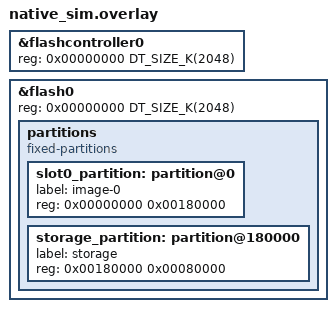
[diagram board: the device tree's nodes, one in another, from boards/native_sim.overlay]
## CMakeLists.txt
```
# SPDX-License-Identifier: GPL-3.0-or-later
#
# Method 3 (PAIRING_PASSKEY) pairing gate conformance on native_sim (T-18).
# Exercises pairing.c + client_bond.c + storage.c on a simulated LittleFS
# partition, with PAIRING_PASSKEY=y selected via prj.conf.
#
# Build:
#   ZEPHYR_TOOLCHAIN_VARIANT=host \
#     west build -p -b native_sim firmware/tests/pairing_passkey --no-sysbuild
#   west build -t run

cmake_minimum_required(VERSION 3.20.0)

find_package(Zephyr REQUIRED HINTS $ENV{ZEPHYR_BASE})
project(pairing_passkey_tests LANGUAGES C)

set(FW ${CMAKE_CURRENT_SOURCE_DIR}/../..)

target_sources(app PRIVATE
    src/main.c
    src/gesture_stub.c
    src/led_stub.c
    src/session_stub.c
    ${FW}/src/clients/pairing.c
    ${FW}/src/clients/client_bond.c
    ${FW}/src/storage/storage.c
    ${FW}/src/storage/volume_marker.c
    ${FW}/src/crypto/device_id.c
    ${FW}/src/crypto/crypto_wolfssl.c
    ${FW}/src/crypto/wc_rand.c
    ${FW}/src/crypto/zeroize.c
    ${FW}/../common/cbor/cantil_cbor.c
)

target_include_directories(app PRIVATE
    ${FW}/src
    ${FW}/include
    ${FW}/../common/cbor
)

zephyr_include_directories(${FW}/include)

# Carries WOLFSSL_USER_SETTINGS / WOLFSSL_ZEPHYR defines.
target_link_libraries(app PRIVATE wolfSSL)
```

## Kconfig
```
# SPDX-License-Identifier: GPL-3.0-or-later

mainmenu "pairing_passkey ztest"

config CANTIL_MAX_KEY_SLOTS
	int "Maximum number of key slots"
	default 8
	range 1 64

config CANTIL_MAX_CLIENT_BONDS
	int "Maximum number of host-client bonds"
	default 2
	range 1 16

config CANTIL_MAX_PEER_BONDS
	int "Maximum number of peer-device bonds"
	default 2
	range 1 8

config CANTIL_CRL_VALIDITY_SEC
	int "CRL nextUpdate window (seconds)"
	default 86400

# Pairing method symbols (flat booleans — no choice wrapper in test context).
config PAIRING_PROMISCUOUS
	bool "Method 0 — Promiscuous"
	default n

config PAIRING_TOFU
	bool "Method 1 — Silent TOFU"
	default n

config PAIRING_TAP_CONFIRM
	bool "Method 2 — Tap-confirmed bond"
	default n

config PAIRING_PASSKEY
	bool "Method 3 — Passkey + tap-confirmed bond"
	default n

config CANTIL_PAIR_TIMEOUT_SEC
	int "Pairing prompt timeout (seconds)"
	default 30

config CANTIL_PASSKEY_TIMEOUT_SEC
	int "Passkey entry timeout (seconds)"
	default 60

config CANTIL_PASSKEY_BLINK_PAUSE_MS
	int "Inter-digit pause during passkey LED blink (milliseconds)"
	default 0

source "Kconfig.zephyr"
```

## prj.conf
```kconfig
# ztest framework
CONFIG_ZTEST=y

# Pairing method under test.
CONFIG_PAIRING_PASSKEY=y
CONFIG_CANTIL_PAIR_TIMEOUT_SEC=30
CONFIG_CANTIL_PASSKEY_TIMEOUT_SEC=60
CONFIG_CANTIL_PASSKEY_BLINK_PAUSE_MS=0

CONFIG_CANTIL_MAX_CLIENT_BONDS=2
CONFIG_CANTIL_MAX_PEER_BONDS=2

# Entropy — native_sim has zephyr,native-posix-rng.
CONFIG_ENTROPY_GENERATOR=y
CONFIG_TEST_RANDOM_GENERATOR=y

# LittleFS on the sim flash partition.
CONFIG_FLASH=y
CONFIG_FLASH_MAP=y
CONFIG_FILE_SYSTEM=y
CONFIG_FILE_SYSTEM_LITTLEFS=y
CONFIG_FS_LITTLEFS_FMP_DEV=y
CONFIG_FILE_SYSTEM_MKFS=y


# Device-id source for the FICR-derived storage key.
CONFIG_HWINFO=y

CONFIG_MAIN_STACK_SIZE=8192
CONFIG_HEAP_MEM_POOL_SIZE=16384

# crc32_ieee — storage.c volume identity marker
CONFIG_CRC=y

# wolfCrypt — primitives selected by the settings header, not Kconfig.
CONFIG_WOLFSSL=y
CONFIG_WOLFSSL_BUILTIN=y
CONFIG_WOLFSSL_SETTINGS_FILE="cantil_wolfssl_user_settings.h"
```

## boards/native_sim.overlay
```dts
/* Same flash layout as session_slot tests — 512 KB storage partition. */

&flashcontroller0 {
	reg = <0x00000000 DT_SIZE_K(2048)>;
};

&flash0 {
	reg = <0x00000000 DT_SIZE_K(2048)>;
	partitions {
		compatible = "fixed-partitions";
		#address-cells = <1>;
		#size-cells = <1>;

		/delete-node/ partition@0;
		/delete-node/ partition@c000;
		/delete-node/ partition@75000;
		/delete-node/ partition@de000;
		/delete-node/ partition@fc000;

		slot0_partition: partition@0 {
			label = "image-0";
			reg = <0x00000000 0x00180000>;
		};
		storage_partition: partition@180000 {
			label = "storage";
			reg = <0x00180000 0x00080000>;
		};
	};
};
```

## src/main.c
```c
/* SPDX-License-Identifier: GPL-3.0-or-later */
/* See LICENSE and LICENSE-EXTENSIONS.md at the repo root. */

/*
 * Method 3 (PAIRING_PASSKEY) pairing gate conformance on native_sim (T-18).
 *
 * Drives pairing.c + client_bond.c + storage.c against a simulated flash
 * partition.  Each test starts from a wiped /clients/ dir via before().
 *
 * Stubs:
 *   gesture_stub.c  — fires pair_confirm callback synchronously
 *   led_stub.c      — no-op LED / blink_digit (BLINK_PAUSE_MS=0 in prj.conf)
 *   session_stub.c  — returns a pre-built passkey-reply frame from session_recv()
 *
 * Passkey interception: pairing.c calls the weak pairing_test_passkey_hook()
 * immediately after generating the random passkey and before session_recv().
 * The strong override here primes the session stub with the correct digits for
 * success tests.  Wrong-passkey tests pre-lock the stub to 999999 so the hook
 * cannot override it.
 *
 * Coverage:
 *   1. Known bond → allowed immediately (no session_recv called).
 *   2. Unknown client, correct passkey + gesture OK → bonded, PSK stored.
 *   3. Unknown client, wrong passkey → -EACCES, ERR_AUTH response, not bonded.
 *   4. Unknown client, transport timeout → -EACCES, not bonded.
 *   5. Unknown client, cap full → -EACCES without any prompt.
 *   6. Unknown client, correct passkey but gesture denied → -EACCES, not bonded.
 */

#include <zephyr/kernel.h>
#include <zephyr/ztest.h>
#include <zephyr/fs/fs.h>
#include <string.h>
#include <errno.h>

#include "clients/pairing.h"
#include "clients/client_bond.h"
#include "gesture/gesture.h"
#include "storage/storage.h"
#include "protocol/protocol.h"

#define LFS_MOUNT   "/lfs"
#define CLIENTS_DIR LFS_MOUNT "/clients"

/* Declared in gesture_stub.c */
void pairing_passkey_test_set_gesture_result(cantil_confirm_result_t r);

/* Declared in session_stub.c */
cantil_session_t *pairing_passkey_test_session(void);
void pairing_passkey_test_set_reply_digits(uint32_t digits);
void pairing_passkey_test_lock_digits(uint32_t digits);
void pairing_passkey_test_set_reply_timeout(void);
uint32_t pairing_passkey_test_last_response_err(void);
void pairing_passkey_test_reset(void);

/* ── Passkey hook ───────────────────────────────────────────────────────── */

/* Strong override of the weak pairing_test_passkey_hook() in pairing.c.
 * Called inside pairing_check_and_bond() after the passkey is generated,
 * before session_recv().  Primes the stub with the real value so tests
 * that expect success see the correct digits. */
void pairing_test_passkey_hook(uint32_t passkey)
{
	/* pairing_passkey_test_set_reply_digits respects the lock, so
	 * tests that pre-lock to a wrong value are unaffected. */
	pairing_passkey_test_set_reply_digits(passkey);
}

/* ── Distinct synthetic Curve25519 pubkeys ──────────────────────────────── */

static const uint8_t PUB_A[32] = {0xAA, 0x01, 0x02, 0x03, 0, 0, 0, 0, 0, 0, 0, 0, 0, 0, 0, 0,
				  0,    0,    0,    0,    0, 0, 0, 0, 0, 0, 0, 0, 0, 0, 0, 0};
static const uint8_t PUB_B[32] = {0xBB, 0x01, 0x02, 0x03, 0, 0, 0, 0, 0, 0, 0, 0, 0, 0, 0, 0,
				  0,    0,    0,    0,    0, 0, 0, 0, 0, 0, 0, 0, 0, 0, 0, 0};
static const uint8_t PUB_C[32] = {0xCC, 0x01, 0x02, 0x03, 0, 0, 0, 0, 0, 0, 0, 0, 0, 0, 0, 0,
				  0,    0,    0,    0,    0, 0, 0, 0, 0, 0, 0, 0, 0, 0, 0, 0};

/* ── Helpers ────────────────────────────────────────────────────────────── */

static void rm_rf_dir(const char *path)
{
	struct fs_dir_t dir;
	struct fs_dirent ent;
	char child[128];

	fs_dir_t_init(&dir);
	if (fs_opendir(&dir, path) != 0) {
		return;
	}
	while (fs_readdir(&dir, &ent) == 0 && ent.name[0] != '\0') {
		snprintf(child, sizeof(child), "%s/%s", path, ent.name);
		if (ent.type == FS_DIR_ENTRY_DIR) {
			rm_rf_dir(child);
		}
		fs_unlink(child);
	}
	fs_closedir(&dir);
	fs_unlink(path);
}

/* ── Suite setup / per-test reset ───────────────────────────────────────── */

static void *suite_setup(void)
{
	zassert_ok(storage_init(), "storage_init failed");

	/*
	 * Mark the fresh volume, as the factory image does — client_bond_add()
	 * refuses to persist on an unmarked, empty volume. Same idiom as
	 * ca_bootstrap/crl_der/pairing_ca_anchor; without it the suite passes
	 * only when it inherits a marked flash.bin from an earlier run.
	 */
	(void)storage_volume_marker_write();
	return NULL;
}

static void before(void *unused)
{
	ARG_UNUSED(unused);
	rm_rf_dir(CLIENTS_DIR);
	pairing_passkey_test_reset();
	pairing_passkey_test_set_gesture_result(CANTIL_CONFIRM_OK);
}

ZTEST_SUITE(pairing_passkey, NULL, suite_setup, before, NULL, NULL);

/* ── Test 1: already-bonded client allowed (no session_recv) ────────────── */

ZTEST(pairing_passkey, test_known_bond_allowed)
{
	zassert_ok(client_bond_add(PUB_A, CLIENT_KIND_HOST, 0), "setup bond");

	/* If session_recv were called it would return an error (timeout). */
	pairing_passkey_test_set_reply_timeout();

	cantil_session_t *s = pairing_passkey_test_session();

	zassert_ok(pairing_check_and_bond(PUB_A, s), "known client rejected");

	uint32_t hosts = 0, peers = 0;

	zassert_ok(client_bond_count(&hosts, &peers), "count failed");
	zassert_equal(hosts, 1, "expected 1 bond, got %u", hosts);
}

/* ── Test 2: correct passkey + gesture confirmed → bonded + PSK stored ──── */

ZTEST(pairing_passkey, test_correct_passkey_bonded)
{
	/* Hook will prime stub with the generated passkey value. */
	cantil_session_t *s = pairing_passkey_test_session();

	zassert_ok(pairing_check_and_bond(PUB_A, s), "Method 3 bond failed");

	zassert_equal(client_bond_exists(PUB_A), 1, "bond not stored after passkey+confirm");

	/* PSK file must exist and be non-empty. */
	uint8_t id[4] = {0xAA, 0x01, 0x02, 0x03};
	uint8_t psk_enc[64];
	size_t psk_enc_len = sizeof(psk_enc);

	zassert_ok(storage_client_bond_psk_read(id, psk_enc, &psk_enc_len), "PSK not stored");
	zassert_true(psk_enc_len > 0, "PSK blob is empty");

	zassert_equal(pairing_passkey_test_last_response_err(), (uint32_t)ERR_OK,
		      "device sent non-OK response on success");
}

/* ── Test 3: wrong passkey → -EACCES + ERR_AUTH, not bonded ────────────── */

ZTEST(pairing_passkey, test_wrong_passkey_rejected)
{
	/* Lock stub to 0. Hook cannot override. generate_passkey() never returns 0,
	 * so this is always a guaranteed mismatch. */
	pairing_passkey_test_lock_digits(0U);

	cantil_session_t *s = pairing_passkey_test_session();
	int rc = pairing_check_and_bond(PUB_A, s);

	zassert_equal(rc, -EACCES, "expected -EACCES on wrong passkey, got %d", rc);
	zassert_equal(client_bond_exists(PUB_A), 0, "bonded despite wrong passkey");
	zassert_equal(pairing_passkey_test_last_response_err(), (uint32_t)ERR_AUTH,
		      "expected ERR_AUTH response, got %u",
		      pairing_passkey_test_last_response_err());
}

/* ── Test 4: transport timeout → -EACCES, not bonded ───────────────────── */

ZTEST(pairing_passkey, test_timeout_rejected)
{
	pairing_passkey_test_set_reply_timeout();

	cantil_session_t *s = pairing_passkey_test_session();
	int rc = pairing_check_and_bond(PUB_A, s);

	zassert_equal(rc, -EACCES, "expected -EACCES on timeout, got %d", rc);
	zassert_equal(client_bond_exists(PUB_A), 0, "bonded despite timeout");
}

/* ── Test 5: cap full → -EACCES without any prompt ─────────────────────── */

ZTEST(pairing_passkey, test_cap_full_rejected)
{
	zassert_ok(client_bond_add(PUB_A, CLIENT_KIND_HOST, 0), "bond A");
	zassert_ok(client_bond_add(PUB_B, CLIENT_KIND_HOST, 0), "bond B");

	pairing_passkey_test_set_reply_timeout(); /* recv would error if called */

	cantil_session_t *s = pairing_passkey_test_session();
	int rc = pairing_check_and_bond(PUB_C, s);

	zassert_equal(rc, -EACCES, "expected -EACCES when cap full, got %d", rc);
	zassert_equal(client_bond_exists(PUB_C), 0, "bonded despite cap");
}

/* ── Test 6: correct passkey but gesture denied → -EACCES, not bonded ───── */

ZTEST(pairing_passkey, test_gesture_denied_rejected)
{
	pairing_passkey_test_set_gesture_result(CANTIL_CONFIRM_DENIED);

	cantil_session_t *s = pairing_passkey_test_session();
	int rc = pairing_check_and_bond(PUB_A, s);

	zassert_equal(rc, -EACCES, "expected -EACCES on denied gesture, got %d", rc);
	zassert_equal(client_bond_exists(PUB_A), 0, "bonded despite denial");
}
```

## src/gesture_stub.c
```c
/* SPDX-License-Identifier: GPL-3.0-or-later */
/* See LICENSE at the repo root. */

/*
 * Gesture stub for the pairing_passkey ztest suite (T-18).
 *
 * gesture_request_pair_confirm() is called by pairing.c (PAIRING_PASSKEY)
 * after the passkey is validated, to get user tap-confirmation.
 * The callback fires synchronously with whatever result was set via
 * pairing_passkey_test_set_gesture_result().
 */

#include "gesture/gesture.h"

static cantil_confirm_result_t stub_result = CANTIL_CONFIRM_OK;

void pairing_passkey_test_set_gesture_result(cantil_confirm_result_t r)
{
	stub_result = r;
}

int gesture_request_pair_confirm(cantil_confirm_cb_t cb, void *user_data)
{
	cb(stub_result, user_data);
	return 0;
}
```

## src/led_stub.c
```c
/* SPDX-License-Identifier: GPL-3.0-or-later */
/* See LICENSE at the repo root. */

/*
 * LED stub for the pairing_passkey ztest suite (T-18).
 *
 * Replaces the real led.c so tests don't need PWM/GPIO hardware.
 * led_blink_digit() is blocking in production but returns immediately here.
 * led_set_idle() and led_set_pattern() are no-ops.
 */

#include <zephyr/kernel.h>
#include "led/led.h"

int led_init(void)
{
	return 0;
}

void led_set_idle(led_pattern_t pattern)
{
	ARG_UNUSED(pattern);
}
void led_play_oneshot(led_pattern_t pattern)
{
	ARG_UNUSED(pattern);
}
void led_set_pattern(led_pattern_t pattern)
{
	ARG_UNUSED(pattern);
}

void led_blink_digit(uint8_t digit)
{
	ARG_UNUSED(digit);
	/* Swallow the inter-group msleep that follows in blink_passkey(). */
}

void led_diag_flash(uint8_t color, uint32_t ms)
{
	ARG_UNUSED(color);
	ARG_UNUSED(ms);
}
```

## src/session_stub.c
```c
/* SPDX-License-Identifier: GPL-3.0-or-later */
/* See LICENSE and LICENSE-EXTENSIONS.md at the repo root. */

/*
 * Session stub for the pairing_passkey ztest suite (T-18).
 *
 * pairing.c (PAIRING_PASSKEY) calls:
 *   session_recv()             — receive the CMD_PAIRING_PASSKEY_REPLY frame
 *   session_send()             — send the response (OK/error)
 *   session_get_local_pubkey() — get device static pubkey for PSK derivation
 *
 * Control functions (called from test main.c):
 *   pairing_passkey_test_session()           — return the stub cantil_session_t
 *   pairing_passkey_test_set_reply_digits(d) — session_recv returns CBOR{cmd=0x73, data=d}
 *   pairing_passkey_test_lock_digits(d)      — same, but ignores hook overrides
 *   pairing_passkey_test_set_reply_timeout() — session_recv returns -ETIMEDOUT
 *   pairing_passkey_test_last_response_err() — last err captured from session_send
 *   pairing_passkey_test_reset()             — clear all state
 *
 * Hook integration: pairing_test_passkey_hook() in test/main.c calls
 * pairing_passkey_test_set_reply_digits() to prime the stub with the correct
 * passkey for success tests.  Tests that want a wrong passkey call
 * pairing_passkey_test_lock_digits(999999) BEFORE starting, so the hook
 * cannot override the value.
 *
 * cantil_session_t must be defined here (it is opaque in session.h).
 */

#include <zephyr/kernel.h>
#include <string.h>
#include <errno.h>

#include "session/session.h"
#include "cantil_cbor.h"
#include "protocol/protocol.h"

/* Minimal concrete struct definition — opaque in session.h. */
struct cantil_session {
	bool established;
};

static struct cantil_session stub_session = {.established = true};

cantil_session_t *pairing_passkey_test_session(void)
{
	return &stub_session;
}

/* ── Test controls ─────────────────────────────────────────────────────── */

static uint32_t stub_digits = 0;
static bool stub_digits_locked = false;
static bool stub_inject_timeout = false;
static uint32_t stub_last_err = UINT32_MAX;

/* Set digits; overridable by the passkey hook (for success tests). */
void pairing_passkey_test_set_reply_digits(uint32_t digits)
{
	if (!stub_digits_locked) {
		stub_digits = digits;
	}
}

/* Set digits AND lock against hook override (for wrong-passkey tests). */
void pairing_passkey_test_lock_digits(uint32_t digits)
{
	stub_digits = digits;
	stub_digits_locked = true;
}

void pairing_passkey_test_set_reply_timeout(void)
{
	stub_inject_timeout = true;
}

uint32_t pairing_passkey_test_last_response_err(void)
{
	return stub_last_err;
}

void pairing_passkey_test_reset(void)
{
	stub_digits = 0;
	stub_digits_locked = false;
	stub_inject_timeout = false;
	stub_last_err = UINT32_MAX;
}

/* ── session API stubs ─────────────────────────────────────────────────── */

int session_recv(cantil_session_t *session, uint8_t *buf, size_t max_len, size_t *received)
{
	ARG_UNUSED(session);

	if (stub_inject_timeout) {
		return -ETIMEDOUT;
	}

	/*
	 * Build a CBOR passkey-reply request:
	 *   data payload = CBOR uint32 (the digits value).
	 *   request      = {cmd: 0x73, seq: 1, data: bstr(<CBOR uint32>)}
	 */
	uint8_t digit_cbor[9];
	size_t digit_cbor_len = 0;

	if (cantil_cbor_emit_uint(digit_cbor, sizeof(digit_cbor), &digit_cbor_len, stub_digits) !=
	    0) {
		return -EIO;
	}

	int n = cantil_cbor_encode_request(buf, max_len, CMD_PAIRING_PASSKEY_REPLY, 1, digit_cbor,
					   digit_cbor_len);

	if (n < 0) {
		return -ENOMEM;
	}
	*received = (size_t)n;
	return 0;
}

int session_send(cantil_session_t *session, const uint8_t *buf, size_t len)
{
	ARG_UNUSED(session);

	uint32_t seq = 0, err = UINT32_MAX;
	const uint8_t *data = NULL;
	size_t data_len = 0;

	if (cantil_cbor_decode_response(buf, len, &seq, &err, &data, &data_len) == 0) {
		stub_last_err = err;
	}
	return 0;
}

int session_get_local_pubkey(cantil_session_t *session, uint8_t pubkey[32])
{
	ARG_UNUSED(session);
	memset(pubkey, 0x55, 32);
	return 0;
}

int session_open(cantil_transport_t *t, const uint8_t *pub, cantil_session_t **out)
{
	ARG_UNUSED(t);
	ARG_UNUSED(pub);
	ARG_UNUSED(out);
	return -ENOSYS;
}

void session_close(cantil_session_t *session)
{
	ARG_UNUSED(session);
}

int session_get_remote_pubkey(cantil_session_t *session, uint8_t pubkey[32])
{
	ARG_UNUSED(session);
	ARG_UNUSED(pubkey);
	return -ENOSYS;
}
```
